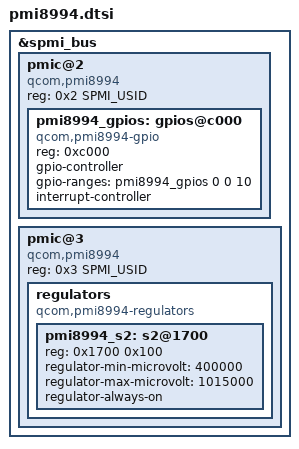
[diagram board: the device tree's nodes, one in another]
// SPDX-License-Identifier: GPL-2.0
#include <dt-bindings/interrupt-controller/irq.h>
#include <dt-bindings/spmi/spmi.h>

&spmi_bus {

	pmic@2 {
		compatible = "qcom,pmi8994", "qcom,spmi-pmic";
		reg = <0x2 SPMI_USID>;
		#address-cells = <1>;
		#size-cells = <0>;

		pmi8994_gpios: gpios@c000 {
			compatible = "qcom,pmi8994-gpio", "qcom,spmi-gpio";
			reg = <0xc000>;
			gpio-controller;
			gpio-ranges = <&pmi8994_gpios 0 0 10>;
			#gpio-cells = <2>;
			interrupt-controller;
			#interrupt-cells = <2>;
		};
	};

	pmic@3 {
		compatible = "qcom,pmi8994", "qcom,spmi-pmic";
		reg = <0x3 SPMI_USID>;
		#address-cells = <1>;
		#size-cells = <0>;

		regulators {
			compatible = "qcom,pmi8994-regulators";
			#address-cells = <1>;
			#size-cells = <1>;

			pmi8994_s2: s2@1700 {
				reg = <0x1700 0x100>;
				status = "ok";
				regulator-min-microvolt = <400000>;
				regulator-max-microvolt = <1015000>;
				regulator-always-on;
			};
		};
	};
};
